# STM32U535 register map
File version: 0.4
CPU: CM33 r0p1, little endian, MPU, FPU, 4 interrupt priority bits
Registers are 32-bit, read-write, reset 0x0 unless marked. A register's access mark holds for its fields unless they carry their own. Offsets are from the block's base; [hi:lo] are bit positions; {n}, {i} and the like mark numbered series.

## DLYBOS — The delay block (DLYB) is used to generate an output clock that is dephased from the input clock
Base 0x420CF000
Same registers: DLYBSD 0x420C8400, SEC_DLYBSD 0x520C8400, SEC_DLYBOS 0x520CF000
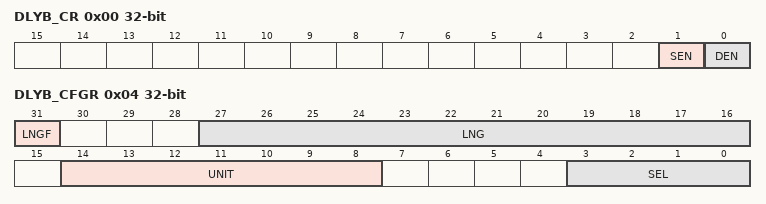
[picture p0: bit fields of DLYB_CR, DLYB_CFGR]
0x00 DLYB_CR — control register
  [1] SEN — OPALPM
  [0] DEN — Operational amplifier Enable
0x04 DLYB_CFGR access per field — configuration register
  [31] LNGF ro, [27:16] LNG ro, [14:8] UNIT rw, [3:0] SEL rw

## EXTI — External interrupt/event controller
Base 0x46022000
Same registers: SEC_EXTI 0x56022000
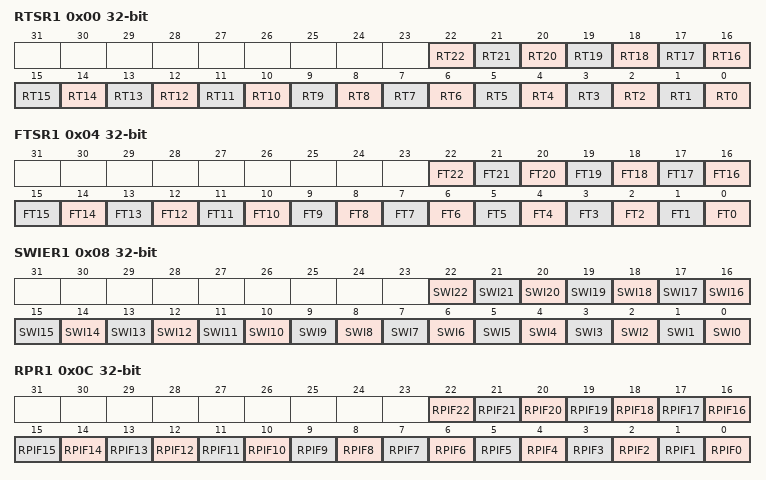
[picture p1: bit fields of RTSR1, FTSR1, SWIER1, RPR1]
0x00 RTSR1 — EXTI rising trigger selection register
  [n] RT{n} (n=0..22) — Rising trigger event configuration bit of configurable event input x
0x04 FTSR1 — EXTI falling trigger selection register
  [n] FT{n} (n=0..22) — Falling trigger event configuration bit of configurable event input x
0x08 SWIER1 — EXTI software interrupt event register
  [n] SWI{n} (n=0..22) — Software interrupt on event x
0x0C RPR1 — EXTI rising edge pending register
  [n] RPIF{n} (n=0..22) — configurable event inputs x rising edge pending bit
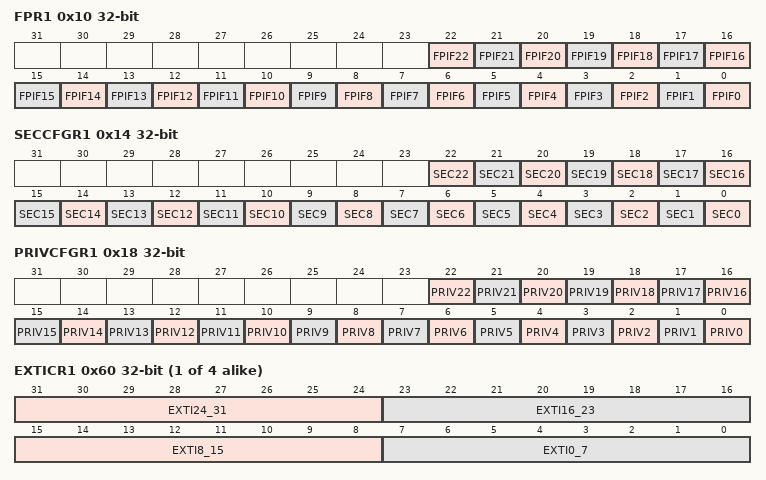
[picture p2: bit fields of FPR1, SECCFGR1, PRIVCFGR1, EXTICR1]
0x10 FPR1 — EXTI falling edge pending register
  [n] FPIF{n} (n=0..22) — configurable event inputs x falling edge pending bit.
0x14 SECCFGR1 — EXTI security configuration register
  [n] SEC{n} (n=0..22) — Security enable on event input x
0x18 PRIVCFGR1 — EXTI privilege configuration register
  [n] PRIV{n} (n=0..22) — Security enable on event input x
{0x5C+4i} EXTICR{i} (i=1..4) — EXTI external interrupt selection register
  [31:24] EXTI24_31 — EXTIm+3 GPIO port selection
  [23:16] EXTI16_23 — EXTIm+2 GPIO port selection
  [15:8] EXTI8_15 — EXTIm+1 GPIO port selection
  [7:0] EXTI0_7 — EXTIm GPIO port selection
0x70 LOCKR — EXTI lock register
  [0] LOCK
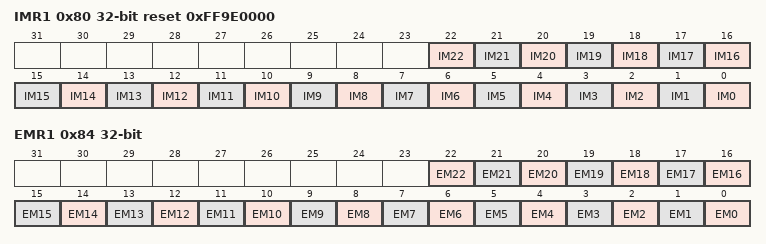
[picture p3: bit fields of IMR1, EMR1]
0x80 IMR1 reset 0xFF9E0000 — EXTI CPU wakeup with interrupt mask register
  [n] IM{n} (n=0..22) — CPU wakeup with interrupt mask on event input
0x84 EMR1 — EXTI CPU wakeup with event mask register
  [n] EM{n} (n=0..22) — CPU wakeup with event generation mask on event input

## FMAC — Filter Math Accelerator
Base 0x40021400
Same registers: SEC_FMAC 0x50021400
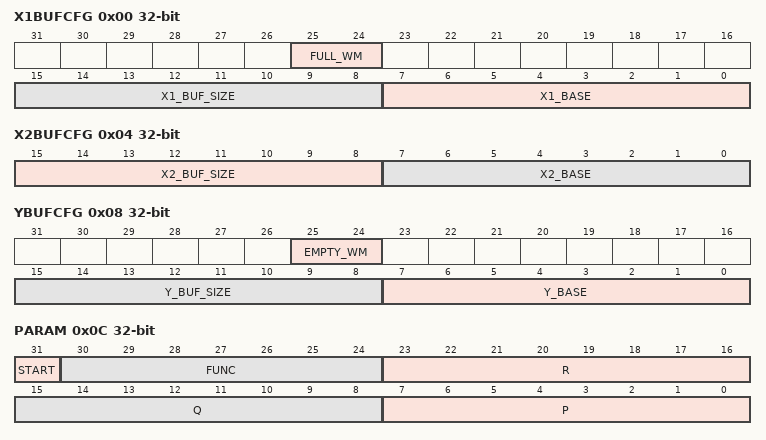
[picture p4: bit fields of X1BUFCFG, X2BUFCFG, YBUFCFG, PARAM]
0x00 X1BUFCFG — FMAC X1 Buffer Configuration register
  [25:24] FULL_WM — Watermark for buffer full flag
  [15:8] X1_BUF_SIZE — Allocated size of X1 buffer in 16-bit words
  [7:0] X1_BASE — Base address of X1 buffer
0x04 X2BUFCFG — FMAC X2 Buffer Configuration register
  [15:8] X2_BUF_SIZE — Size of X2 buffer in 16-bit words
  [7:0] X2_BASE — Base address of X2 buffer
0x08 YBUFCFG — FMAC Y Buffer Configuration register
  [25:24] EMPTY_WM — Watermark for buffer empty flag
  [15:8] Y_BUF_SIZE — Size of Y buffer in 16-bit words
  [7:0] Y_BASE — Base address of Y buffer
0x0C PARAM — FMAC Parameter register
  [31] START — Enable execution
  [30:24] FUNC — Function
  [23:16] R — Input parameter R
  [15:8] Q — Input parameter Q
  [7:0] P — Input parameter P
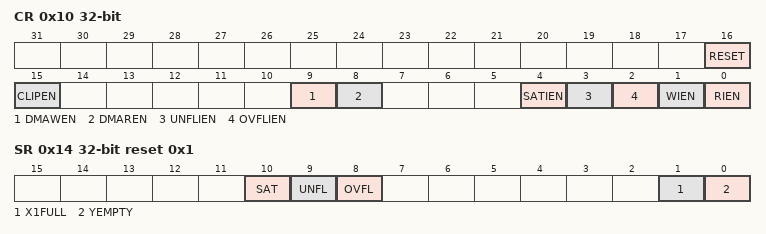
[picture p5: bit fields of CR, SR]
0x10 CR — FMAC Control register
  [16] RESET — Reset FMAC unit
  [15] CLIPEN — Enable clipping
  [9] DMAWEN — Enable DMA write channel requests
  [8] DMAREN — Enable DMA read channel requests
  [4] SATIEN — Enable saturation error interrupts
  [3] UNFLIEN — Enable underflow error interrupts
  [2] OVFLIEN — Enable overflow error interrupts
  [1] WIEN — Enable write interrupt
  [0] RIEN — Enable read interrupt
0x14 SR ro reset 0x1 — FMAC Status register
  [10] SAT — Saturation error flag
  [9] UNFL — Underflow error flag
  [8] OVFL — Overflow error flag
  [1] X1FULL — X1 buffer full flag
  [0] YEMPTY — Y buffer empty flag
0x18 WDATA wo — FMAC Write Data register
  [15:0] WDATA — Write data
0x1C RDATA ro — FMAC Read Data register
  [15:0] RDATA — Read data

## GTZC1_MPCBB1
Base 0x40032C00
Same registers: SEC_GTZC1_MPCBB1 0x50032C00
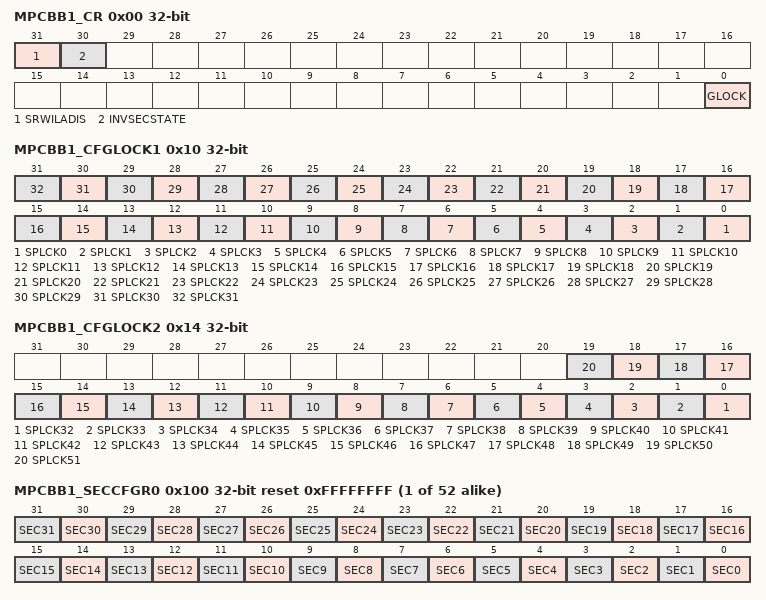
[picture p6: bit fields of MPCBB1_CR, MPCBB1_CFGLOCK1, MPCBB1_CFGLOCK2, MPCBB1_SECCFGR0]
0x00 MPCBB1_CR — MPCBB control register
  [31] SRWILADIS — secure read/write illegal access disable
  [30] INVSECSTATE — SRAMx clocks security state
  [0] GLOCK — lock the control register of the MPCBB until next reset
0x10 MPCBB1_CFGLOCK1 — GTZC1 SRAMz MPCBB configuration lock register 1
  [n] SPLCK{n} (n=0..31)
0x14 MPCBB1_CFGLOCK2 — GTZC1 SRAMz MPCBB configuration lock register 2
  [n-32] SPLCK{n} (n=32..51)
{0x100+4i} MPCBB1_SECCFGR{i} reset 0xFFFFFFFF (i=0..51) — MPCBBx security configuration for super-block x register
  [n] SEC{n} (n=0..31)
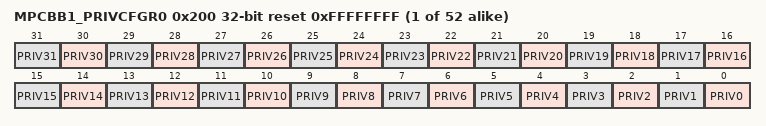
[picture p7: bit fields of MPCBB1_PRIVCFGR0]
{0x200+4i} MPCBB1_PRIVCFGR{i} reset 0xFFFFFFFF (i=0..51) — MPCBB privileged configuration for super-block x register
  [n] PRIV{n} (n=0..31)
